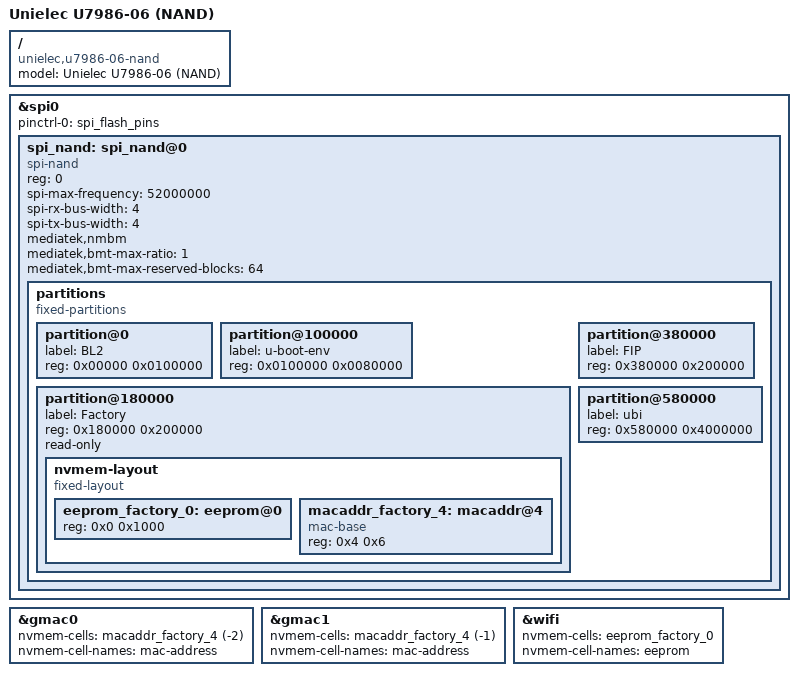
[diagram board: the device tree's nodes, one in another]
// SPDX-License-Identifier: GPL-2.0-or-later OR MIT
/*
 * Copyright (C) 2023 Allen Zhao <allenzhao@unielecinc.com>
 */

/dts-v1/;
#include "mt7986a-unielec-u7986-06.dtsi"

/ {
	model = "Unielec U7986-06 (NAND)";
	compatible = "unielec,u7986-06-nand", "mediatek,mt7986";
};

&spi0 {
	pinctrl-names = "default";
	pinctrl-0 = <&spi_flash_pins>;
	status = "okay";

	spi_nand: spi_nand@0 {
		compatible = "spi-nand";
		reg = <0>;
		#address-cells = <1>;
		#size-cells = <1>;
		spi-max-frequency = <52000000>;
		spi-rx-bus-width = <4>;
		spi-tx-bus-width = <4>;
		mediatek,nmbm;
		mediatek,bmt-max-ratio = <1>;
		mediatek,bmt-max-reserved-blocks = <64>;

		partitions {
			compatible = "fixed-partitions";
			#address-cells = <1>;
			#size-cells = <1>;

			partition@0 {
				label = "BL2";
				reg = <0x00000 0x0100000>;
			};

			partition@100000 {
				label = "u-boot-env";
				reg = <0x0100000 0x0080000>;
			};

			partition@180000 {
				label = "Factory";
				reg = <0x180000 0x200000>;
				read-only;

				nvmem-layout {
					compatible = "fixed-layout";
					#address-cells = <1>;
					#size-cells = <1>;

					eeprom_factory_0: eeprom@0 {
						reg = <0x0 0x1000>;
					};

					macaddr_factory_4: macaddr@4 {
						compatible = "mac-base";
						reg = <0x4 0x6>;
						#nvmem-cell-cells = <1>;
					};
				};
			};

			partition@380000 {
				label = "FIP";
				reg = <0x380000 0x200000>;
			};

			partition@580000 {
				label = "ubi";
				reg = <0x580000 0x4000000>;
			};
		};
	};
};

&gmac0 {
	nvmem-cells = <&macaddr_factory_4 (-2)>;
	nvmem-cell-names = "mac-address";
};

&gmac1 {
	nvmem-cells = <&macaddr_factory_4 (-1)>;
	nvmem-cell-names = "mac-address";
};

&wifi {
	nvmem-cells = <&eeprom_factory_0>;
	nvmem-cell-names = "eeprom";
	status = "okay";
};
